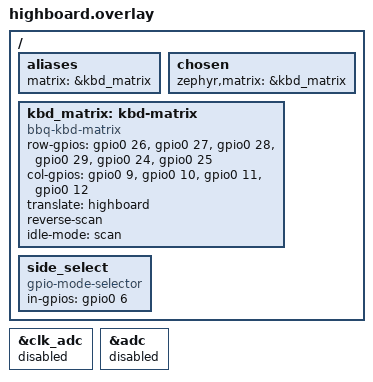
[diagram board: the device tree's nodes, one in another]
/* Device tree overlay for Proto2 keyboard matrix
 *
 * This board only supports the sparkfun_promicro_rp2040 board, which is mounted
 * directly onto the board, so we don't use the connector, but just directly
 * attach to the GPIOs.
 */

/ {
	aliases {
		matrix = &kbd_matrix;
	};

	chosen {
		zephyr,matrix = &kbd_matrix;
	};

	kbd_matrix: kbd-matrix {
		compatible = "bbq-kbd-matrix";
		row-gpios = <&gpio0 26 (GPIO_PULL_DOWN | GPIO_ACTIVE_HIGH)>,
			    <&gpio0 27 (GPIO_PULL_DOWN | GPIO_ACTIVE_HIGH)>,
			    <&gpio0 28 (GPIO_PULL_DOWN | GPIO_ACTIVE_HIGH)>,
			    <&gpio0 29 (GPIO_PULL_DOWN | GPIO_ACTIVE_HIGH)>,
			    <&gpio0 24 (GPIO_PULL_DOWN | GPIO_ACTIVE_HIGH)>,
			    <&gpio0 25 (GPIO_PULL_DOWN | GPIO_ACTIVE_HIGH)>;
		col-gpios = <&gpio0 9 GPIO_ACTIVE_HIGH>,
			    <&gpio0 10 GPIO_ACTIVE_HIGH>,
			    <&gpio0 11 GPIO_ACTIVE_HIGH>,
			    <&gpio0 12 GPIO_ACTIVE_HIGH>;
                translate = "highboard";
                reverse-scan;
		idle-mode = "scan";
	};

        side_select {
                compatible = "gpio-mode-selector";
                in-gpios = <&gpio0 6 (GPIO_PULL_UP | GPIO_ACTIVE_HIGH)>;
        };
};

&clk_adc {
        status = "disabled";
};

&adc {
        status = "disabled";
};
